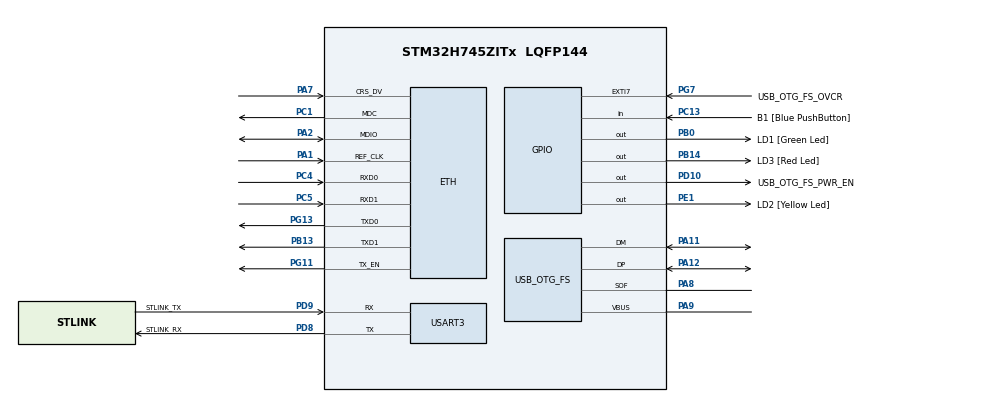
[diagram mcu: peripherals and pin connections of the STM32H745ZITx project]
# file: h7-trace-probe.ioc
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PH0-OSC_IN\ (PH0).PinAttribute=CortexM7
PB14.GPIO_Label=LD3 [Red Led]
RCC.PLLFRACN=0
PC5.Mode=RMII
PB13.Signal=ETH_TXD1
PG13.Signal=ETH_TXD0
RCC.SYSCLKSource=RCC_SYSCLKSOURCE_PLLCLK
USART3.VirtualMode-Asynchronous=VM_ASYNC
PA14\ (JTCK/SWCLK).Signal=DEBUG_JTCK-SWCLK
PB0.Stacked=true
PE2.Mode=Trace_Synchro_4bits_SW
PD8.Signal=USART3_TX
PE5.Signal=DEBUG_TRACED2
PE1.Signal=GPIO_Output
RCC.DIVM3=1
RCC.DIVM1=8
PD8.PinAttribute=CortexM7
VP_SYS_M4_VS_Systick.Mode=SysTick
PE2.Signal=DEBUG_TRACECLK
PA8.Signal=USB_OTG_FS_SOF
PA14\ (JTCK/SWCLK).Mode=Trace_Synchro_4bits_SW
CortexM7.Pins=PC13,PB0,PD10,PG7,PE1
PA7.PinAttribute=CortexM7
Mcu.Package=LQFP144
RCC.PLL3FRACN=0
PC14-OSC32_IN\ (OSC32_IN).Mode=LSE-External-Oscillator
RCC.APB4Freq_Value=120000000
PB13.Mode=RMII
PH0-OSC_IN\ (PH0).Mode=HSE-External-Clock-Source
RCC.SupplySource=PWR_DIRECT_SMPS_SUPPLY
PC4.Mode=RMII
RCC.DIVQ3=4
LWIP0.BSP.i2caddr=0
PD9.GPIO_Label=STLINK_TX
PA1.PinAttribute=CortexM7
PC13.Signal=GPIO_Input
USB_DEVICE_M7.VirtualMode-CDC_FS=Cdc
PA9.PinAttribute=CortexM7
PG13.PinAttribute=CortexM7
PD10.Signal=GPIO_Output
PA12.PinAttribute=CortexM7
PA2.PinAttribute=CortexM7
PA9.Signal=USB_OTG_FS_VBUS
RCC.DIVN3=24
RCC.DIVN1=480
PD8.Mode=Asynchronous
PB14.Signal=GPIO_Output
RCC.USBCLockSelection=RCC_USBCLKSOURCE_PLL3
PG11.PinAttribute=CortexM7
PE1.GPIO_Label=LD2 [Yellow Led]
PA1.Mode=RMII
PE6.Mode=Trace_Synchro_4bits_SW
PA11.PinAttribute=CortexM7
PG7.GPIO_Label=USB_OTG_FS_OVCR
PE1.PinAttribute=CortexM7
NVIC1.OTG_FS_IRQn=true\:0\:0\:false\:false\:true\:false\:true
PE2.PinAttribute=CortexM7
ETH.MediaInterface=HAL_ETH_RMII_MODE
PA8.PinAttribute=CortexM7
PG11.Mode=RMII
PA11.Signal=USB_OTG_FS_DM
ProjectManager.HeapSize=0x200
LWIP.Version=v2.1.2_Cube
PD9.PinAttribute=CortexM7
PA14\ (JTCK/SWCLK).PinAttribute=CortexM7
PE3.Signal=DEBUG_TRACED0
PA8.Mode=Activate_SOF_FS
PC1.PinAttribute=CortexM7
PB0.Signal=GPIO_Output
PC1.Signal=ETH_MDC
PA13\ (JTMS/SWDIO).Signal=DEBUG_JTMS-SWDIO
PC1.Mode=RMII
Mcu.Family=STM32H7
LWIP0.BSP.STBoard=false
RCC.CortexFreq_Value=240000000
PG7.PinAttribute=CortexM7
RCC.HPRE=RCC_HCLK_DIV2
PH0-OSC_IN\ (PH0).Signal=RCC_OSC_IN
PC15-OSC32_OUT\ (OSC32_OUT).Mode=LSE-External-Oscillator
PA11.Mode=Device_Only
PB0.GPIO_Label=LD1 [Green Led]
RCC.PLL2FRACN=0
PC13.GPIO_Label=B1 [Blue PushButton]
PD9.Mode=Asynchronous
PE3.PinAttribute=CortexM7
PE4.PinAttribute=CortexM7
PG11.Signal=ETH_TX_EN
ProjectManager.StackSize=0x400
PA12.Signal=USB_OTG_FS_DP
RCC.HCLKFreq_Value=120000000
USB_DEVICE_M7.VirtualModeFS=Cdc_FS
PB0.PinAttribute=CortexM7
RCC.HSE_VALUE=8000000
PA13\ (JTMS/SWDIO).PinAttribute=CortexM7
NVIC2.PriorityGroup=NVIC_PRIORITYGROUP_4
PG13.Mode=RMII
PE4.Mode=Trace_Synchro_4bits_SW
CortexM7.IPs=FATFS_M7\:I,FREERTOS_M7\:I,IWDG1\:I,RCC\:I,WWDG1\:I,DMA\:I,BDMA\:I,MDMA\:I,NVIC1\:I,SYS\:I,USART3\:I,USB_OTG_FS\:I,ETH\:I,CORTEX_M7\:I,DEBUG\:I,USB_DEVICE_M7\:I,USB_HOST_M7\:I,PDM2PCM_M7\:I,PWR\:I,RESMGR_UTILITY\:I,OPENAMP_M7\:I,VREFBUF\:I,LWIP\:I,USB_OTG_HS\:I,QUADSPI\:I
LWIP0.BSP.solution=LAN8742
PE4.Signal=DEBUG_TRACED1
PD10.PinAttribute=CortexM7
RCC.APB3Freq_Value=120000000
USB_DEVICE_M7.CLASS_NAME_FS=CDC
LWIP0.BSP.component=LAN8742
USB_OTG_FS.VirtualMode=Device_Only
PC5.Signal=ETH_RXD1
PE3.Mode=Trace_Synchro_4bits_SW
VP_USB_DEVICE_M7_VS_USB_DEVICE_CDC_FS.Mode=CDC_FS
PH1-OSC_OUT\ (PH1).PinAttribute=CortexM7
PB14.PinAttribute=CortexM4
CORTEX_M7.CPU_ICache=Enabled
PG7.Signal=GPXTI7
PA7.Mode=RMII
PA13\ (JTMS/SWDIO).Mode=Trace_Synchro_4bits_SW
CortexM4.Pins=PB14
PC4.Signal=ETH_RXD0
NVIC1.PriorityGroup=NVIC_PRIORITYGROUP_4
PD9.Signal=USART3_RX
PH1-OSC_OUT\ (PH1).Signal=RCC_OSC_OUT
VP_LWIP_VS_Enabled.Mode=Enabled
PB13.PinAttribute=CortexM7
PD8.GPIO_Label=STLINK_RX
PA9.Mode=Activate_VBUS
ProjectManager.TargetToolchain=STM32CubeIDE
PC15-OSC32_OUT\ (OSC32_OUT).Signal=RCC_OSC32_OUT
PC14-OSC32_IN\ (OSC32_IN).PinAttribute=CortexM7
PC4.PinAttribute=CortexM7
LWIP0.BSP.instance=LAN8742
RCC.USBFreq_Value=48000000
PD10.GPIO_Label=USB_OTG_FS_PWR_EN
LWIP0.BSP.api=BSP_COMPONENT_DRIVER
PA1.Signal=ETH_REF_CLK
board=NUCLEO-H745ZI-Q
RCC.APB2Freq_Value=120000000
PE5.Mode=Trace_Synchro_4bits_SW
RCC.ADCFreq_Value=16125000
PE6.Signal=DEBUG_TRACED3
Mcu.Name=STM32H745ZITx
PA2.Signal=ETH_MDIO
PE6.PinAttribute=CortexM7
PC13.PinAttribute=CortexM7
RCC.SYSCLKFreq_VALUE=240000000
PE5.PinAttribute=CortexM7
PA12.Mode=Device_Only
LWIP.BSP.number=1
PC14-OSC32_IN\ (OSC32_IN).Signal=RCC_OSC32_IN
PC15-OSC32_OUT\ (OSC32_OUT).PinAttribute=CortexM7
PA2.Mode=RMII
PC5.PinAttribute=CortexM7
CORTEX_M7.CPU_DCache=Enabled
LWIP0.BSP.name=Driver_PHY
RCC.APB1Freq_Value=120000000
PA7.Signal=ETH_CRS_DV
CortexM4.IPs=FATFS_M4\:I,FREERTOS_M4\:I,IWDG2\:I,RCC,WWDG2\:I,DMA,BDMA,MDMA,NVIC2\:I,USART3,DEBUG,USB_DEVICE_M4\:I,USB_HOST_M4\:I,PDM2PCM_M4\:I,PWR,RESMGR_UTILITY,SYS_M4\:I,CORTEX_M4\:I,OPENAMP_M4\:I,VREFBUF

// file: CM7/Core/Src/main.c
/* USER CODE BEGIN Header */
/**
  ******************************************************************************
  * @file           : main.c
  * @brief          : Main program body
  ******************************************************************************
  * @attention
  *
  * <h2><center>&copy; Copyright (c) 2020 STMicroelectronics.
  * All rights reserved.</center></h2>
  *
  * This software component is licensed by ST under Ultimate Liberty license
  * SLA0044, the "License"; You may not use this file except in compliance with
  * the License. You may obtain a copy of the License at:
  *                             www.st.com/SLA0044
  *
  ******************************************************************************
  */
/* USER CODE END Header */
#include "main.h"
#include "lwip.h"
#include "usart.h"
#include "usb_device.h"
#include "gpio.h"

/* USER CODE BEGIN PD */

#define HSEM_ID_0 (0U) /* HW semaphore 0*/
/* USER CODE END PD */

void SystemClock_Config(void);

int main(void)
{

/* USER CODE BEGIN Boot_Mode_Sequence_0 */
  int32_t timeout;
/* USER CODE END Boot_Mode_Sequence_0 */

  /* Enable I-Cache---------------------------------------------------------*/
  SCB_EnableICache();

  /* Enable D-Cache---------------------------------------------------------*/
  SCB_EnableDCache();

/* USER CODE BEGIN Boot_Mode_Sequence_1 */
  /* Wait until CPU2 boots and enters in stop mode or timeout*/
  timeout = 0xFFFF;
  while((__HAL_RCC_GET_FLAG(RCC_FLAG_D2CKRDY) != RESET) && (timeout-- > 0));
  if ( timeout < 0 )
  {
  Error_Handler();
  }
/* USER CODE END Boot_Mode_Sequence_1 */
  /* MCU Configuration--------------------------------------------------------*/

  /* Reset of all peripherals, Initializes the Flash interface and the Systick. */
  HAL_Init();

  /* Configure the system clock */
  SystemClock_Config();
/* USER CODE BEGIN Boot_Mode_Sequence_2 */
/* When system initialization is finished, Cortex-M7 will release Cortex-M4 by means of
HSEM notification */
/*HW semaphore Clock enable*/
__HAL_RCC_HSEM_CLK_ENABLE();
/*Take HSEM */
HAL_HSEM_FastTake(HSEM_ID_0);
/*Release HSEM in order to notify the CPU2(CM4)*/
HAL_HSEM_Release(HSEM_ID_0,0);
/* wait until CPU2 wakes up from stop mode */
timeout = 0xFFFF;
while((__HAL_RCC_GET_FLAG(RCC_FLAG_D2CKRDY) == RESET) && (timeout-- > 0));
if ( timeout < 0 )
{
Error_Handler();
}
/* USER CODE END Boot_Mode_Sequence_2 */

  /* Initialize all configured peripherals */
  MX_GPIO_Init();
  MX_USART3_UART_Init();
  MX_USB_DEVICE_Init();
  MX_LWIP_Init();

  /* Infinite loop */
  /* USER CODE BEGIN WHILE */
#pragma clang diagnostic push
#pragma ide diagnostic ignored "EndlessLoop"
  while (1)
  {
    HAL_GPIO_TogglePin(LD2_GPIO_Port,LD2_Pin);
    HAL_Delay(330);

	  /* USER CODE END WHILE */

    /* USER CODE BEGIN 3 */
  }
#pragma clang diagnostic pop
  /* USER CODE END 3 */
}

void SystemClock_Config(void)
{
  RCC_OscInitTypeDef RCC_OscInitStruct = {0};
  RCC_ClkInitTypeDef RCC_ClkInitStruct = {0};
  RCC_PeriphCLKInitTypeDef PeriphClkInitStruct = {0};

  /** Supply configuration update enable
  */
  HAL_PWREx_ConfigSupply(PWR_DIRECT_SMPS_SUPPLY);
  /** Configure the main internal regulator output voltage
  */
  __HAL_PWR_VOLTAGESCALING_CONFIG(PWR_REGULATOR_VOLTAGE_SCALE2);

  while(!__HAL_PWR_GET_FLAG(PWR_FLAG_VOSRDY)) {}
  /** Macro to configure the PLL clock source
  */
  __HAL_RCC_PLL_PLLSOURCE_CONFIG(RCC_PLLSOURCE_HSE);
  /** Initializes the RCC Oscillators according to the specified parameters
  * in the RCC_OscInitTypeDef structure.
  */
  RCC_OscInitStruct.OscillatorType = RCC_OSCILLATORTYPE_HSE;
  RCC_OscInitStruct.HSEState = RCC_HSE_BYPASS;
  RCC_OscInitStruct.PLL.PLLState = RCC_PLL_ON;
  RCC_OscInitStruct.PLL.PLLSource = RCC_PLLSOURCE_HSE;
  RCC_OscInitStruct.PLL.PLLM = 8;
  RCC_OscInitStruct.PLL.PLLN = 480;
  RCC_OscInitStruct.PLL.PLLP = 2;
  RCC_OscInitStruct.PLL.PLLQ = 2;
  RCC_OscInitStruct.PLL.PLLR = 2;
  RCC_OscInitStruct.PLL.PLLRGE = RCC_PLL1VCIRANGE_0;
  RCC_OscInitStruct.PLL.PLLVCOSEL = RCC_PLL1VCOWIDE;
  RCC_OscInitStruct.PLL.PLLFRACN = 0;
  if (HAL_RCC_OscConfig(&RCC_OscInitStruct) != HAL_OK)
  {
    Error_Handler();
  }
  /** Initializes the CPU, AHB and APB buses clocks
  */
  RCC_ClkInitStruct.ClockType = RCC_CLOCKTYPE_HCLK|RCC_CLOCKTYPE_SYSCLK
                              |RCC_CLOCKTYPE_PCLK1|RCC_CLOCKTYPE_PCLK2
                              |RCC_CLOCKTYPE_D3PCLK1|RCC_CLOCKTYPE_D1PCLK1;
  RCC_ClkInitStruct.SYSCLKSource = RCC_SYSCLKSOURCE_PLLCLK;
  RCC_ClkInitStruct.SYSCLKDivider = RCC_SYSCLK_DIV1;
  RCC_ClkInitStruct.AHBCLKDivider = RCC_HCLK_DIV2;
  RCC_ClkInitStruct.APB3CLKDivider = RCC_APB3_DIV1;
  RCC_ClkInitStruct.APB1CLKDivider = RCC_APB1_DIV1;
  RCC_ClkInitStruct.APB2CLKDivider = RCC_APB2_DIV1;
  RCC_ClkInitStruct.APB4CLKDivider = RCC_APB4_DIV1;

  if (HAL_RCC_ClockConfig(&RCC_ClkInitStruct, FLASH_LATENCY_1) != HAL_OK)
  {
    Error_Handler();
  }
  PeriphClkInitStruct.PeriphClockSelection = RCC_PERIPHCLK_USART3|RCC_PERIPHCLK_USB;
  PeriphClkInitStruct.PLL3.PLL3M = 1;
  PeriphClkInitStruct.PLL3.PLL3N = 24;
  PeriphClkInitStruct.PLL3.PLL3P = 2;
  PeriphClkInitStruct.PLL3.PLL3Q = 4;
  PeriphClkInitStruct.PLL3.PLL3R = 2;
  PeriphClkInitStruct.PLL3.PLL3RGE = RCC_PLL3VCIRANGE_3;
  PeriphClkInitStruct.PLL3.PLL3VCOSEL = RCC_PLL3VCOWIDE;
  PeriphClkInitStruct.PLL3.PLL3FRACN = 0;
  PeriphClkInitStruct.Usart234578ClockSelection = RCC_USART234578CLKSOURCE_D2PCLK1;
  PeriphClkInitStruct.UsbClockSelection = RCC_USBCLKSOURCE_PLL3;
  if (HAL_RCCEx_PeriphCLKConfig(&PeriphClkInitStruct) != HAL_OK)
  {
    Error_Handler();
  }
  /** Enable USB Voltage detector
  */
  HAL_PWREx_EnableUSBVoltageDetector();
}

void Error_Handler(void)
{
}

/************************ (C) COPYRIGHT STMicroelectronics *****END OF FILE****/
